# MSPM0G350X register map
Vendor: Texas Instruments; File version: This preliminary header file does not have a version number - build date: 2023-02-21 16:25:48
CPU: CM0 r0p1, little endian, MPU, no FPU, 3 interrupt priority bits
Registers are 32-bit, read-write, reset 0x0 unless marked. A register's access mark holds for its fields unless they carry their own. Offsets are from the block's base; [hi:lo] are bit positions; {n}, {i} and the like mark numbered series.

## CANFD0 (part 2 of 2) — PERIPHERALREGION
Base 0x40508000
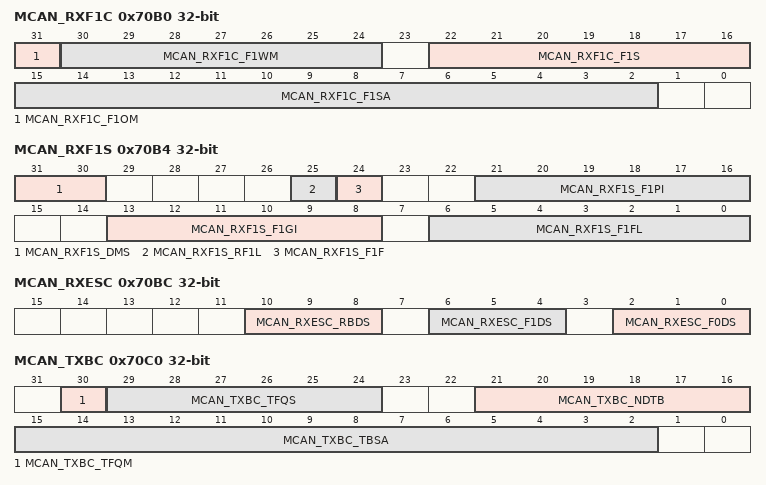
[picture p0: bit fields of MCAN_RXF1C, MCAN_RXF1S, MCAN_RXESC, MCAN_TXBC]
0x70B0 MCAN_RXF1C — MCAN Rx FIFO 1 Configuration
  [31] MCAN_RXF1C_F1OM — FIFO 1 Operation Mode. FIFO 1 can be operated in blocking or in overwrite mode. 0 FIFO 1 blocking mode 1 FIFO 1 overwrite mode Qualified Write is possible only with CCCR.CCE='1' and CCCR.INIT='1'.
  [30:24] MCAN_RXF1C_F1WM — Rx FIFO 1 Watermark 0 Watermark interrupt disabled 1-64 Level for Rx FIFO 1 watermark interrupt (IR.RF1W) >64 Watermark interrupt disabled Qualified Write is possible only with CCCR.CCE='1' and CCCR.INIT='1'.
  [22:16] MCAN_RXF1C_F1S — Rx FIFO 1 Size. The Rx FIFO 1 elements are indexed from 0 to F1S - 1. 0 No Rx FIFO 1 1-64 Number of Rx FIFO 1 elements >64 Values greater than 64 are interpreted as 64 Qualified Write is possible only with CCCR.CCE='1' and CCCR.INIT='1'.
  [15:2] MCAN_RXF1C_F1SA — Rx FIFO 1 Start Address Start address of Rx FIFO 1 in Message RAM (32-bit word address).
0x70B4 MCAN_RXF1S ro — MCAN Rx FIFO 1 Status
  [31:30] MCAN_RXF1S_DMS — Debug Message Status 00 Idle state, wait for reception of debug messages 01 Debug message A received 10 Debug messages A, B received 11 Debug messages A, B, C received
  [25] MCAN_RXF1S_RF1L — Rx FIFO 1 Message Lost. This bit is a copy of interrupt flag IR.RF1L. When IR.RF1L is reset, this bit is also reset. 0 No Rx FIFO 1 message lost 1 Rx FIFO 1 message lost, also set after write attempt to Rx FIFO 1 of size zero Note: Overwriting the oldest message when RXF1C.F1OM = '1' will not set this flag.
  [24] MCAN_RXF1S_F1F — Rx FIFO 1 Full 0 Rx FIFO 1 not full 1 Rx FIFO 1 full
  [21:16] MCAN_RXF1S_F1PI — Rx FIFO 1 Put Index. Rx FIFO 1 write index pointer, range 0 to 63.
  [13:8] MCAN_RXF1S_F1GI — Rx FIFO 1 Get Index. Rx FIFO 1 read index pointer, range 0 to 63.
  [6:0] MCAN_RXF1S_F1FL — Rx FIFO 1 Fill Level. Number of elements stored in Rx FIFO 1, range 0 to 64.
0x70B8 MCAN_RXF1A — MCAN Rx FIFO 1 Acknowledge
  [5:0] MCAN_RXF1A_F1AI — Rx FIFO 1 Acknowledge Index. After the Host has read a message or a sequence of messages from Rx FIFO 1 it has to write the buffer index of the last element read from Rx FIFO 1 to F1AI. This will set the Rx FIFO 1 Get Index RXF1S.F1GI to F1AI + 1 and update the FIFO 1 Fill Level RXF1S.F1FL.
0x70BC MCAN_RXESC — MCAN Rx Buffer / FIFO Element Size Configuration
  [10:8] MCAN_RXESC_RBDS — Rx Buffer Data Field Size 000 8 byte data field 001 12 byte data field 010 16 byte data field 011 20 byte data field 100 24 byte data field 101 32 byte data field 110 48 byte data field 111 64 byte data field Note: In case the data field size of an accepted CAN frame exceeds the data field size configured for the matching Rx Buffer or Rx FIFO, only the number of bytes as configured by RXESC are stored to the Rx Buffer resp. Rx FIFO element. The rest of the frame's data field is ignored. Qualified Write is possible only with CCCR.CCE='1' and CCCR.INIT='1'.
  [6:4] MCAN_RXESC_F1DS — Rx FIFO 1 Data Field Size 000 8 byte data field 001 12 byte data field 010 16 byte data field 011 20 byte data field 100 24 byte data field 101 32 byte data field 110 48 byte data field 111 64 byte data field Note: In case the data field size of an accepted CAN frame exceeds the data field size configured for the matching Rx Buffer or Rx FIFO, only the number of bytes as configured by RXESC are stored to the Rx Buffer resp. Rx FIFO element. The rest of the frame's data field is ignored. Qualified Write is possible only with CCCR.CCE='1' and CCCR.INIT='1'.
  [2:0] MCAN_RXESC_F0DS — Rx FIFO 0 Data Field Size 000 8 byte data field 001 12 byte data field 010 16 byte data field 011 20 byte data field 100 24 byte data field 101 32 byte data field 110 48 byte data field 111 64 byte data field Note: In case the data field size of an accepted CAN frame exceeds the data field size configured for the matching Rx Buffer or Rx FIFO, only the number of bytes as configured by RXESC are stored to the Rx Buffer resp. Rx FIFO element. The rest of the frame's data field is ignored. Qualified Write is possible only with CCCR.CCE='1' and CCCR.INIT='1'.
0x70C0 MCAN_TXBC — MCAN Tx Buffer Configuration
  [30] MCAN_TXBC_TFQM — Tx FIFO/Queue Mode 0 Tx FIFO operation 1 Tx Queue operation Qualified Write is possible only with CCCR.CCE='1' and CCCR.INIT='1'.
  [29:24] MCAN_TXBC_TFQS — Transmit FIFO/Queue Size 0 No Tx FIFO/Queue 1-32 Number of Tx Buffers used for Tx FIFO/Queue >32 Values greater than 32 are interpreted as 32 Note: Be aware that the sum of TFQS and NDTB may be not greater than 32. There is no check for erroneous configurations. The Tx Buffers section in the Message RAM starts with the dedicated Tx Buffers. Qualified Write is possible only with CCCR.CCE='1' and CCCR.INIT='1'.
  [21:16] MCAN_TXBC_NDTB — Number of Dedicated Transmit Buffers 0 No Dedicated Tx Buffers 1-32 Number of Dedicated Tx Buffers >32 Values greater than 32 are interpreted as 32 Note: Be aware that the sum of TFQS and NDTB may be not greater than 32. There is no check for erroneous configurations. The Tx Buffers section in the Message RAM starts with the dedicated Tx Buffers. Qualified Write is possible only with CCCR.CCE='1' and CCCR.INIT='1'.
  [15:2] MCAN_TXBC_TBSA — Tx Buffers Start Address. Start address of Tx Buffers section in Message RAM (32-bit word address). Qualified Write is possible only with CCCR.CCE='1' and CCCR.INIT='1'.
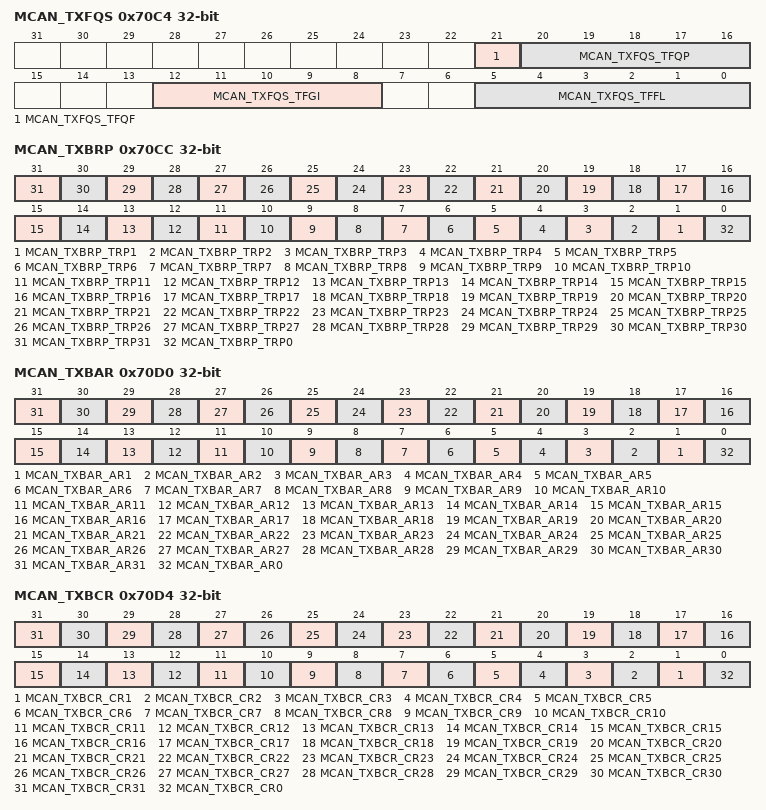
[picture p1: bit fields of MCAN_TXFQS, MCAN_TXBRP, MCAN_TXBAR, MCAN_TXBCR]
0x70C4 MCAN_TXFQS ro — MCAN Tx FIFO / Queue Status
  [21] MCAN_TXFQS_TFQF — Tx FIFO/Queue Full 0 Tx FIFO/Queue not full 1 Tx FIFO/Queue full
  [20:16] MCAN_TXFQS_TFQP — Tx FIFO/Queue Put Index. Tx FIFO/Queue write index pointer, range 0 to 31. Note: In case of mixed configurations where dedicated Tx Buffers are combined with a Tx FIFO or a Tx Queue, the Put and Get Indices indicate the number of the Tx Buffer starting with the first dedicated Tx Buffers. Example: For a configuration of 12 dedicated Tx Buffers and a Tx FIFO of 20 Buffers a Put Index of 15 points to the fourth buffer of the Tx FIFO.
  [12:8] MCAN_TXFQS_TFGI — Tx FIFO Get Index. Tx FIFO read index pointer, range 0 to 31. Read as zero when Tx Queue operation is configured (TXBC.TFQM = '1'). Note: In case of mixed configurations where dedicated Tx Buffers are combined with a Tx FIFO or a Tx Queue, the Put and Get Indices indicate the number of the Tx Buffer starting with the first dedicated Tx Buffers. Example: For a configuration of 12 dedicated Tx Buffers and a Tx FIFO of 20 Buffers a Put Index of 15 points to the fourth buffer of the Tx FIFO.
  [5:0] MCAN_TXFQS_TFFL — Tx FIFO Free Level. Number of consecutive free Tx FIFO elements starting from TFGI, range 0 to 32. Read as zero when Tx Queue operation is configured (TXBC.TFQM = '1').
0x70C8 MCAN_TXESC — MCAN Tx Buffer Element Size Configuration
  [2:0] MCAN_TXESC_TBDS — Tx Buffer Data Field Size 000 8 byte data field 001 12 byte data field 010 16 byte data field 011 20 byte data field 100 24 byte data field 101 32 byte data field 110 48 byte data field 111 64 byte data field Note: In case the data length code DLC of a Tx Buffer element is configured to a value higher than the Tx Buffer data field size TXESC.TBDS, the bytes not defined by the Tx Buffer are transmitted as &quot;0xCC&quot; (padding bytes). Qualified Write is possible only with CCCR.CCE='1' and CCCR.INIT='1'.
0x70CC MCAN_TXBRP ro — MCAN Tx Buffer Request Pending
  [n] MCAN_TXBRP_TRP{n} (n=1..31) — Transmission Request Pending {n}. See description for bit 0.
  [0] MCAN_TXBRP_TRP0 — Transmission Request Pending 0. Each Tx Buffer has its own Transmission Request Pending bit. The bits are set via register TXBAR. The bits are reset after a requested transmission has completed or has been cancelled via register TXBCR. TXBRP bits are set only for those Tx Buffers configured via TXBC. After a TXBRP bit has been set, a Tx scan is started to check for the pending Tx request with the highest priority (Tx Buffer with lowest Message ID). A cancellation request resets the corresponding transmission request pending bit of register TXBRP. In case a transmission has already been started when a cancellation is requested, this is done at the end of the transmission, regardless whether the transmission was successful or not. The cancellation request bits are reset directly after the corresponding TXBRP bit has been reset. After a cancellation has been requested, a finished cancellation is signalled via TXBCF - after successful transmission together with the corresponding TXBTO bit - when the transmission has not yet been started at the point of cancellation - when the transmission has been aborted due to lost arbitration - when an error occurred during frame transmission In DAR mode all transmissions are automatically cancelled if they are not successful. The corresponding TXBCF bit is set for all unsuccessful transmissions. 0 No transmission request pending 1 Transmission request pending Note: TXBRP bits which are set while a Tx scan is in progress are not considered during this particular Tx scan. In case a cancellation is requested for such a Tx Buffer, this Add Request is cancelled immediately, the corresponding TXBRP bit is reset.
0x70D0 MCAN_TXBAR — MCAN Tx Buffer Add Request
  [n] MCAN_TXBAR_AR{n} (n=1..31) — Add Request {n}. See description for bit 0.
  [0] MCAN_TXBAR_AR0 — Add Request 0. Each Tx Buffer has its own Add Request bit. Writing a '1' will set the corresponding Add Request bit; writing a '0' has no impact. This enables the Host to set transmission requests for multiple Tx Buffers with one write to TXBAR. TXBAR bits are set only for those Tx Buffers configured via TXBC. When no Tx scan is running, the bits are reset immediately, else the bits remain set until the Tx scan process has completed. 0 No transmission request added 1 Transmission requested added Note: If an add request is applied for a Tx Buffer with pending transmission request (corresponding TXBRP bit already set), this add request is ignored. Qualified Write is possible only with CCCR.CCE='0'
0x70D4 MCAN_TXBCR — MCAN Tx Buffer Cancellation Request
  [n] MCAN_TXBCR_CR{n} (n=1..31) — Cancellation Request {n}. See description for bit 0.
  [0] MCAN_TXBCR_CR0 — Cancellation Request 0. Each Tx Buffer has its own Cancellation Request bit. Writing a '1' will set the corresponding Cancellation Request bit; writing a '0' has no impact. This enables the Host to set cancellation requests for multiple Tx Buffers with one write to TXBCR. TXBCR bits are set only for those Tx Buffers configured via TXBC. The bits remain set until the corresponding bit of TXBRP is reset. 0 No cancellation pending 1 Cancellation pending Qualified Write is possible only with CCCR.CCE='0'
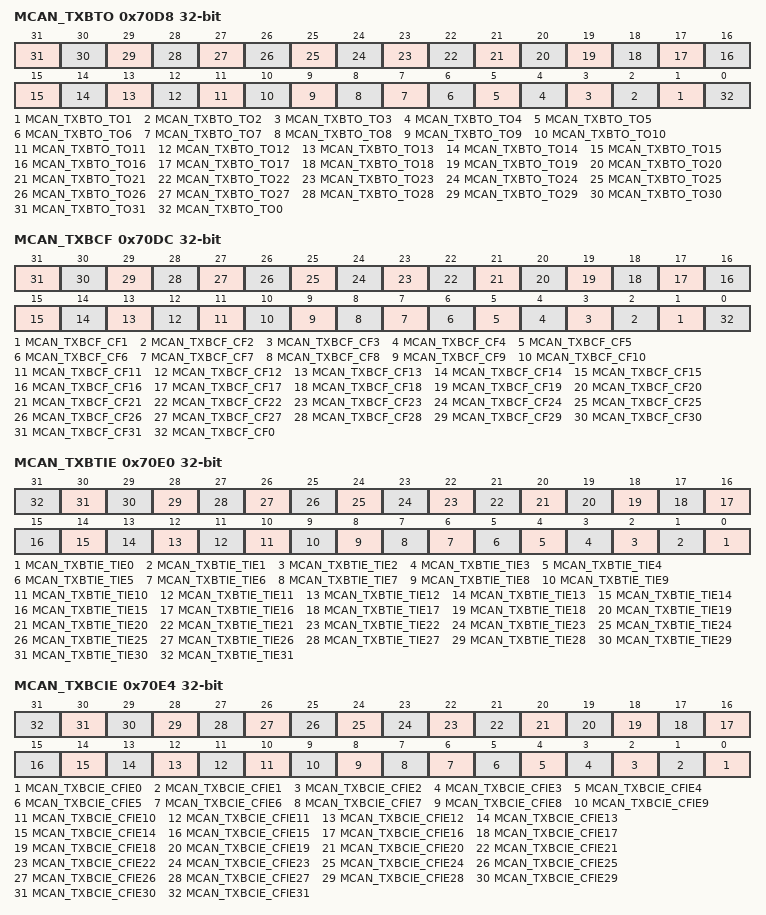
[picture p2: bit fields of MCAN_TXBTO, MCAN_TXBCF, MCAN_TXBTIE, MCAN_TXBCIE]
0x70D8 MCAN_TXBTO ro — MCAN Tx Buffer Transmission Occurred
  [n] MCAN_TXBTO_TO{n} (n=1..31) — Transmission Occurred {n}. See description for bit 0.
  [0] MCAN_TXBTO_TO0 — Transmission Occurred 0. Each Tx Buffer has its own Transmission Occurred bit. The bits are set when the corresponding TXBRP bit is cleared after a successful transmission. The bits are reset when a new transmission is requested by writing a '1' to the corresponding bit of register TXBAR. 0 No transmission occurred 1 Transmission occurred
0x70DC MCAN_TXBCF ro — MCAN Tx Buffer Cancellation Finished
  [n] MCAN_TXBCF_CF{n} (n=1..31) — Cancellation Finished {n}. See description for bit 0.
  [0] MCAN_TXBCF_CF0 — Cancellation Finished 0. Each Tx Buffer has its own Cancellation Finished bit. The bits are set when the corresponding TXBRP bit is cleared after a cancellation was requested via TXBCR. In case the corresponding TXBRP bit was not set at the point of cancellation, CF is set immediately. The bits are reset when a new transmission is requested by writing a '1' to the corresponding bit of register TXBAR. 0 No transmit buffer cancellation 1 Transmit buffer cancellation finished
0x70E0 MCAN_TXBTIE — MCAN Tx Buffer Transmission Interrupt Enable
  [n] MCAN_TXBTIE_TIE{n} (n=0..31) — Transmission Interrupt Enable {n}. Each Tx Buffer has its own Transmission Interrupt Enable bit. 0 Transmission interrupt disabled 1 Transmission interrupt enable
0x70E4 MCAN_TXBCIE — MCAN Tx Buffer Cancellation Finished Interrupt Enable
  [n] MCAN_TXBCIE_CFIE{n} (n=0..31) — Cancellation Finished Interrupt Enable {n}. Each Tx Buffer has its own Cancellation Finished Interrupt Enable bit. 0 Cancellation finished interrupt disabled 1 Cancellation finished interrupt enabled
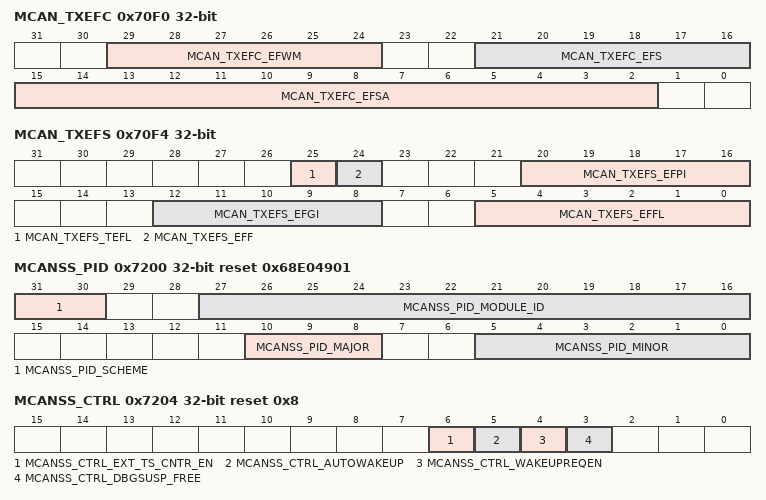
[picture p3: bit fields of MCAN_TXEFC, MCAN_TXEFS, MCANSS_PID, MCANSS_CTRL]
0x70F0 MCAN_TXEFC — MCAN Tx Event FIFO Configuration
  [29:24] MCAN_TXEFC_EFWM — Event FIFO Watermark 0 Watermark interrupt disabled 1-32 Level for Tx Event FIFO watermark interrupt (IR.TEFW) >32 Watermark interrupt disabled
  [21:16] MCAN_TXEFC_EFS — Event FIFO Size. The Tx Event FIFO elements are indexed from 0 to EFS - 1. 0 Tx Event FIFO disabled 1-32 Number of Tx Event FIFO elements >32 Values greater than 32 are interpreted as 32
  [15:2] MCAN_TXEFC_EFSA — Event FIFO Start Address. Start address of Tx Event FIFO in Message RAM (32-bit word address).
0x70F4 MCAN_TXEFS ro — MCAN Tx Event FIFO Status
  [25] MCAN_TXEFS_TEFL — Tx Event FIFO Element Lost. This bit is a copy of interrupt flag IR.TEFL. When IR.TEFL is reset, this bit is also reset. 0 No Tx Event FIFO element lost 1 Tx Event FIFO element lost, also set after write attempt to Tx Event FIFO of size zero.
  [24] MCAN_TXEFS_EFF — Event FIFO Full 0 Tx Event FIFO not full 1 Tx Event FIFO full
  [20:16] MCAN_TXEFS_EFPI — Event FIFO Put Index.Tx Event FIFO write index pointer, range 0 to 31.
  [12:8] MCAN_TXEFS_EFGI — Event FIFO Get Index. Tx Event FIFO read index pointer, range 0 to 31.
  [5:0] MCAN_TXEFS_EFFL — Event FIFO Fill Level. Number of elements stored in Tx Event FIFO, range 0 to 32.
0x70F8 MCAN_TXEFA — MCAN Tx Event FIFO Acknowledge
  [4:0] MCAN_TXEFA_EFAI — Event FIFO Acknowledge Index. After the Host has read an element or a sequence of elements from the Tx Event FIFO it has to write the index of the last element read from Tx Event FIFO to EFAI. This will set the Tx Event FIFO Get Index TXEFS.EFGI to EFAI + 1 and update the Event FIFO Fill Level TXEFS.EFFL.
0x7200 MCANSS_PID ro reset 0x68E04901 — MCAN Subsystem Revision Register
  [31:30] MCANSS_PID_SCHEME — PID Register Scheme
  [27:16] MCANSS_PID_MODULE_ID — Module Identification Number
  [10:8] MCANSS_PID_MAJOR — Major Revision of the MCAN Subsystem
  [5:0] MCANSS_PID_MINOR — Minor Revision of the MCAN Subsystem
0x7204 MCANSS_CTRL reset 0x8 — MCAN Subsystem Control Register
  [6] MCANSS_CTRL_EXT_TS_CNTR_EN — External Timestamp Counter Enable. 0 External timestamp counter disabled 1 External timestamp counter enabled
  [5] MCANSS_CTRL_AUTOWAKEUP — Automatic Wakeup Enable. Enables the MCANSS to automatically clear the MCAN CCCR.INIT bit, fully waking the MCAN up, on an enabled wakeup request. 0 Disable the automatic write to CCCR.INIT 1 Enable the automatic write to CCCR.INIT
  [4] MCANSS_CTRL_WAKEUPREQEN — Wakeup Request Enable. Enables the MCANSS to wakeup on CAN RXD activity. 0 Disable wakeup request 1 Enables wakeup request
  [3] MCANSS_CTRL_DBGSUSP_FREE — Debug Suspend Free Bit. Enables debug suspend. 0 Disable debug suspend 1 Enable debug suspend
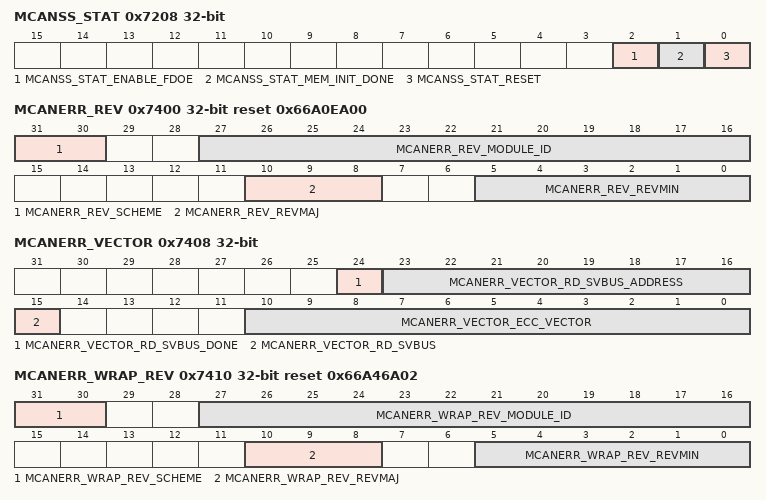
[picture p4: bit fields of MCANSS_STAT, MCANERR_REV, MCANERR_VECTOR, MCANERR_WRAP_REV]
0x7208 MCANSS_STAT ro (reset mask 0xFFFFFFFB) — MCAN Subsystem Status Register
  [2] MCANSS_STAT_ENABLE_FDOE — Flexible Datarate Operation Enable. Determines whether CAN FD operation may be enabled via the MCAN core CCCR.FDOE bit (bit 8) or if only standard CAN operation is possible with this instance of the MCAN. 0 MCAN is only capable of standard CAN communication 1 MCAN may be configured to perform CAN FD communication
  [1] MCANSS_STAT_MEM_INIT_DONE — Memory Initialization Done. 0 Message RAM initialization is in progress 1 Message RAM is initialized for use
  [0] MCANSS_STAT_RESET — Soft Reset Status. 0 Not in reset 1 Reset is in progress
0x720C MCANSS_ICS — MCAN Subsystem Interrupt Clear Shadow Register
  [0] MCANSS_ICS_EXT_TS_CNTR_OVFL — External Timestamp Counter Overflow Interrupt Status Clear. Reads always return a 0. 0 Write of '0' has no effect 1 Write of '1' clears the MCANSS_IRS.EXT_TS_CNTR_OVFL bit
0x7210 MCANSS_IRS — MCAN Subsystem Interrupt Raw Satus Register
  [0] MCANSS_IRS_EXT_TS_CNTR_OVFL — External Timestamp Counter Overflow Interrupt Status. This bit is set by HW or by a SW write of '1'. To clear, use the MCANSS_ICS.EXT_TS_CNTR_OVFL bit. 0 External timestamp counter has not overflowed 1 External timestamp counter has overflowed When this bit is set to '1' by HW or SW, the MCANSS_EXT_TS_UNSERVICED_INTR_CNTR.EXT_TS_INTR_CNTR bit field will increment by 1.
0x7214 MCANSS_IECS — MCAN Subsystem Interrupt Enable Clear Shadow Register
  [0] MCANSS_IECS_EXT_TS_CNTR_OVFL — External Timestamp Counter Overflow Interrupt Enable Clear. Reads always return a 0. 0 Write of '0' has no effect 1 Write of '1' clears the MCANSS_IES.EXT_TS_CNTR_OVFL bit
0x7218 MCANSS_IE — MCAN Subsystem Interrupt Enable Register
  [0] MCANSS_IE_EXT_TS_CNTR_OVFL — External Timestamp Counter Overflow Interrupt Enable. A write of '0' has no effect. A write of '1' sets the MCANSS_IES.EXT_TS_CNTR_OVFL bit.
0x721C MCANSS_IES ro — MCAN Subsystem Interrupt Enable Status
  [0] MCANSS_IES_EXT_TS_CNTR_OVFL — External Timestamp Counter Overflow Interrupt Enable Status. To set, use the CANSS_IE.EXT_TS_CNTR_OVFL bit. To clear, use the MCANSS_IECS.EXT_TS_CNTR_OVFL bit. 0 External timestamp counter overflow interrupt is not enabled 1 External timestamp counter overflow interrupt is enabled
0x7220 MCANSS_EOI — MCAN Subsystem End of Interrupt
  [7:0] MCANSS_EOI_EOI — End of Interrupt. A write to this register will clear the associated interrupt. If the unserviced interrupt counter is > 1, another interrupt is generated. 0x00 External TS Interrupt is cleared 0x01 MCAN(0) interrupt is cleared 0x02 MCAN(1) interrupt is cleared Other writes are ignored.
0x7224 MCANSS_EXT_TS_PRESCALER — MCAN Subsystem External Timestamp Prescaler 0
  [23:0] MCANSS_EXT_TS_PRESCALER_PRESCALER — External Timestamp Prescaler Reload Value. The external timestamp count rate is the host (system) clock rate divided by this value, except in the case of 0. A zero value in this bit field will act identically to a value of 0x000001.
0x7228 MCANSS_EXT_TS_UNSERVICED_INTR_CNTR ro — MCAN Subsystem External Timestamp Unserviced Interrupts Counter
  [4:0] MCANSS_EXT_TS_UNSERVICED_INTR_CNTR_EXT_TS_INTR_CNTR — External Timestamp Counter Unserviced Rollover Interrupts. If this value is > 1, an MCANSS_EOI write of '1' to bit 0 will issue another interrupt. The status of this bit field is affected by the MCANSS_IRS.EXT_TS_CNTR_OVFL bit field.
0x7400 MCANERR_REV ro reset 0x66A0EA00 — MCAN Error Aggregator Revision Register
  [31:30] MCANERR_REV_SCHEME — PID Register Scheme
  [27:16] MCANERR_REV_MODULE_ID — Module Identification Number
  [10:8] MCANERR_REV_REVMAJ — Major Revision of the Error Aggregator
  [5:0] MCANERR_REV_REVMIN — Minor Revision of the Error Aggregator
0x7408 MCANERR_VECTOR — MCAN ECC Vector Register
  [24] MCANERR_VECTOR_RD_SVBUS_DONE ro — Read Completion Flag
  [23:16] MCANERR_VECTOR_RD_SVBUS_ADDRESS — Read Address Offset
  [15] MCANERR_VECTOR_RD_SVBUS — Read Trigger
  [10:0] MCANERR_VECTOR_ECC_VECTOR — ECC RAM ID. Each error detection and correction (EDC) controller has a bank of error registers (offsets 0x10 - 0x3B) associated with it. These registers are accessed via an internal serial bus (SVBUS). To access them through the ECC aggregator the controller ID desired must be written to the ECC_VECTOR field, together with the RD_SVBUS trigger and RD_SVBUS_ADDRESS bit field. This initiates the serial read which consummates by setting the RD_SVBUS_DONE bit. At this point the addressed register may be read by a normal CPU read of the appropriate offset address. 0x000 Message RAM ECC controller is selected Others Reserved (do not use) Subsequent writes through the SVBUS (offsets 0x10 - 0x3B) have a delayed completion. To avoid conflicts, perform a read back of a register within this range after writing.
0x740C MCANERR_STAT ro reset 0x2 — MCAN Error Misc Status
  [10:0] MCANERR_STAT_NUM_RAMS — Number of RAMs. Number of ECC RAMs serviced by the aggregator.
0x7410 MCANERR_WRAP_REV ro reset 0x66A46A02 — MCAN ECC Wrapper Revision Register
  [31:30] MCANERR_WRAP_REV_SCHEME — PID Register Scheme
  [27:16] MCANERR_WRAP_REV_MODULE_ID — Module Identification Number
  [10:8] MCANERR_WRAP_REV_REVMAJ — Major Revision of the Error Aggregator
  [5:0] MCANERR_WRAP_REV_REVMIN — Minor Revision of the Error Aggregator
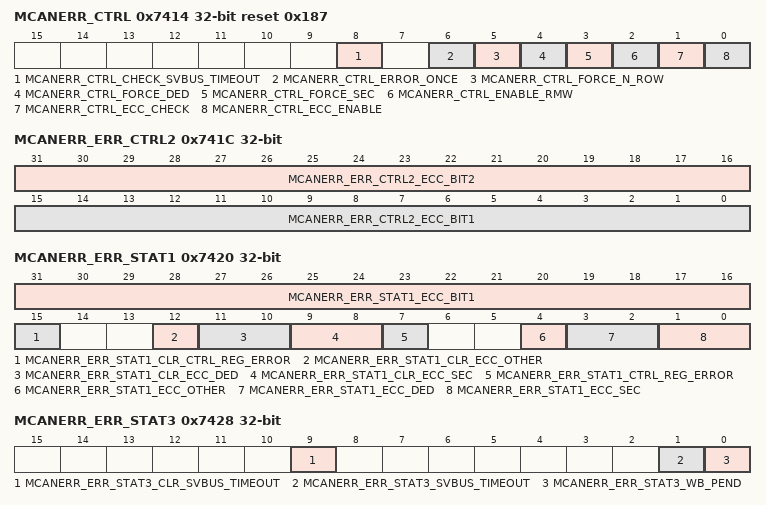
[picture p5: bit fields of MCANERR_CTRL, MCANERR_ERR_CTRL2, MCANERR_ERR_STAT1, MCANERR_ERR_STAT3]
0x7414 MCANERR_CTRL reset 0x187 — MCAN ECC Control
  [8] MCANERR_CTRL_CHECK_SVBUS_TIMEOUT — Enables Serial VBUS timeout mechanism
  [6] MCANERR_CTRL_ERROR_ONCE — If this bit is set, the FORCE_SEC/FORCE_DED will inject an error to the specified row only once. The FORCE_SEC bit will be cleared once a writeback happens. If writeback is not enabled, this error will be cleared the cycle following the read when the data is corrected. For double-bit errors, the FORCE_DED bit will be cleared the cycle following the double-bit error. Any subsequent reads will not force an error.
  [5] MCANERR_CTRL_FORCE_N_ROW — Enable single/double-bit error on the next RAM read, regardless of the MCANERR_ERR_CTRL1.ECC_ROW setting. For write through mode, this applies to writes as well as reads.
  [4] MCANERR_CTRL_FORCE_DED — Force double-bit error. Cleared the cycle following the error if ERROR_ONCE is asserted. For write through mode, this applies to writes as well as reads. MCANERR_ERR_CTRL1 and MCANERR_ERR_CTRL2 should be configured prior to setting this bit.
  [3] MCANERR_CTRL_FORCE_SEC — Force single-bit error. Cleared on a writeback or the cycle following the error if ERROR_ONCE is asserted. For write through mode, this applies to writes as well as reads. MCANERR_ERR_CTRL1 and MCANERR_ERR_CTRL2 should be configured prior to setting this bit.
  [2] MCANERR_CTRL_ENABLE_RMW — Enable read-modify-write on partial word writes
  [1] MCANERR_CTRL_ECC_CHECK — Enable ECC Check. ECC is completely bypassed if both ECC_ENABLE and ECC_CHECK are '0'.
  [0] MCANERR_CTRL_ECC_ENABLE — Enable ECC Generation
0x7418 MCANERR_ERR_CTRL1 — MCAN ECC Error Control 1 Register
  [31:0] MCANERR_ERR_CTRL1_ECC_ROW — Row address where FORCE_SEC or FORCE_DED needs to be applied. This is ignored if FORCE_N_ROW is set.
0x741C MCANERR_ERR_CTRL2 — MCAN ECC Error Control 2 Register
  [31:16] MCANERR_ERR_CTRL2_ECC_BIT2 — Second column/data bit that needs to be flipped when FORCE_DED is set
  [15:0] MCANERR_ERR_CTRL2_ECC_BIT1 — Column/Data bit that needs to be flipped when FORCE_SEC or FORCE_DED is set
0x7420 MCANERR_ERR_STAT1 — MCAN ECC Error Status 1 Register
  [31:16] MCANERR_ERR_STAT1_ECC_BIT1 ro — ECC Error Bit Position. Indicates the bit position in the RAM data that is in error on an SEC error. Only valid on an SEC error. 0 Bit 0 is in error 1 Bit 1 is in error 2 Bit 2 is in error 3 Bit 3 is in error ... 31 Bit 31 is in error >32 Invalid
  [15] MCANERR_ERR_STAT1_CLR_CTRL_REG_ERROR — Writing a '1' clears the CTRL_REG_ERROR bit
  [12] MCANERR_ERR_STAT1_CLR_ECC_OTHER — Writing a '1' clears the ECC_OTHER bit.
  [11:10] MCANERR_ERR_STAT1_CLR_ECC_DED — Clear ECC_DED. A write of a non-zero value to this bit field decrements the ECC_DED bit field by the value provided.
  [9:8] MCANERR_ERR_STAT1_CLR_ECC_SEC — Clear ECC_SEC. A write of a non-zero value to this bit field decrements the ECC_SEC bit field by the value provided.
  [7] MCANERR_ERR_STAT1_CTRL_REG_ERROR — Control Register Error. A bit field in the control register is in an ambiguous state. This means that the redundancy registers have detected a state where not all values are the same and has defaulted to the reset state. S/W needs to re-write these registers to a known state. A write of 1 will set this interrupt flag.
  [4] MCANERR_ERR_STAT1_ECC_OTHER — SEC While Writeback Error Status 0 No SEC error while writeback pending 1 Indicates that successive single-bit errors have occurred while a writeback is still pending
  [3:2] MCANERR_ERR_STAT1_ECC_DED — Double Bit Error Detected Status. A 2-bit saturating counter of the number of DED errors that have occurred since last cleared. 0 No double-bit error detected 1 One double-bit error was detected 2 Two double-bit errors were detected 3 Three double-bit errors were detected A write of a non-zero value to this bit field increments it by the value provided.
  [1:0] MCANERR_ERR_STAT1_ECC_SEC — Single Bit Error Corrected Status. A 2-bit saturating counter of the number of SEC errors that have occurred since last cleared. 0 No single-bit error detected 1 One single-bit error was detected and corrected 2 Two single-bit errors were detected and corrected 3 Three single-bit errors were detected and corrected A write of a non-zero value to this bit field increments it by the value provided.
0x7424 MCANERR_ERR_STAT2 ro — MCAN ECC Error Status 2 Register
  [31:0] MCANERR_ERR_STAT2_ECC_ROW — Indicates the row address where the single or double-bit error occurred. This value is address offset/4.
0x7428 MCANERR_ERR_STAT3 — MCAN ECC Error Status 3 Register
  [9] MCANERR_ERR_STAT3_CLR_SVBUS_TIMEOUT — Write 1 to clear the Serial VBUS Timeout Flag
  [1] MCANERR_ERR_STAT3_SVBUS_TIMEOUT — Serial VBUS Timeout Flag. Write 1 to set.
  [0] MCANERR_ERR_STAT3_WB_PEND ro — Delayed Write Back Pending Status 0 No write back pending 1 An ECC data correction write back is pending
0x743C MCANERR_SEC_EOI — MCAN Single Error Corrected End of Interrupt Register
  [0] MCANERR_SEC_EOI_EOI_WR — Write to this register indicates that software has acknowledged the pending interrupt and the next interrupt can be sent to the host. Note that a write to the MCANERR_ERR_STAT1.CLR_ECC_SEC goes through the SVBUS and has a delayed completion. To avoid an additional interrupt, read the MCANERR_ERR_STAT1 register back prior to writing to this bit field.
0x7440 MCANERR_SEC_STATUS — MCAN Single Error Corrected Interrupt Status Register
  [0] MCANERR_SEC_STATUS_MSGMEM_PEND ro — Message RAM SEC Interrupt Pending 0 No SEC interrupt is pending 1 SEC interrupt is pending
0x7480 MCANERR_SEC_ENABLE_SET — MCAN Single Error Corrected Interrupt Enable Set Register
  [0] MCANERR_SEC_ENABLE_SET_MSGMEM_ENABLE_SET — Message RAM SEC Interrupt Pending Enable Set. Writing a 1 to this bit enables the Message RAM SEC error interrupts. Writing a 0 has no effect. Reads return the corresponding enable bit's current value.
0x74C0 MCANERR_SEC_ENABLE_CLR — MCAN Single Error Corrected Interrupt Enable Clear Register
  [0] MCANERR_SEC_ENABLE_CLR_MSGMEM_ENABLE_CLR — Message RAM SEC Interrupt Pending Enable Clear. Writing a 1 to this bit disables the Message RAM SEC error interrupts. Writing a 0 has no effect. Reads return the corresponding enable bit's current value.
0x753C MCANERR_DED_EOI — MCAN Double Error Detected End of Interrupt Register
  [0] MCANERR_DED_EOI_EOI_WR — Write to this register indicates that software has acknowledged the pending interrupt and the next interrupt can be sent to the host. Note that a write to the MCANERR_ERR_STAT1.CLR_ECC_DED goes through the SVBUS and has a delayed completion. To avoid an additional interrupt, read the MCANERR_ERR_STAT1 register back prior to writing to this bit field.
0x7540 MCANERR_DED_STATUS — MCAN Double Error Detected Interrupt Status Register
  [0] MCANERR_DED_STATUS_MSGMEM_PEND ro — Message RAM DED Interrupt Pending 0 No DED interrupt is pending 1 DED interrupt is pending
0x7580 MCANERR_DED_ENABLE_SET — MCAN Double Error Detected Interrupt Enable Set Register
  [0] MCANERR_DED_ENABLE_SET_MSGMEM_ENABLE_SET — Message RAM DED Interrupt Pending Enable Set. Writing a 1 to this bit enables the Message RAM DED error interrupts. Writing a 0 has no effect. Reads return the corresponding enable bit's current value.
0x75C0 MCANERR_DED_ENABLE_CLR — MCAN Double Error Detected Interrupt Enable Clear Register
  [0] MCANERR_DED_ENABLE_CLR_MSGMEM_ENABLE_CLR — Message RAM DED Interrupt Pending Enable Clear. Writing a 1 to this bit disables the Message RAM DED error interrupts. Writing a 0 has no effect. Reads return the corresponding enable bit's current value.
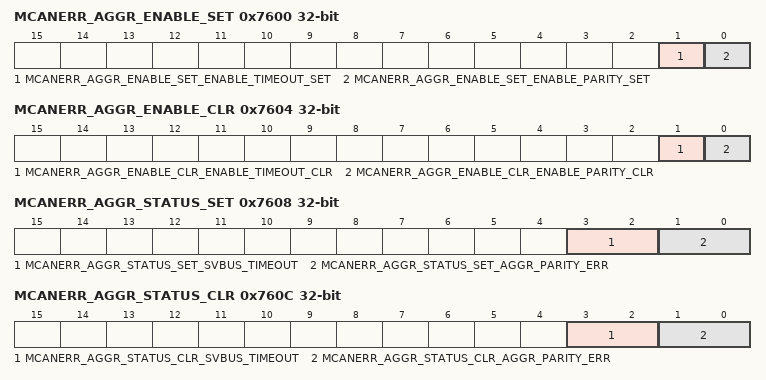
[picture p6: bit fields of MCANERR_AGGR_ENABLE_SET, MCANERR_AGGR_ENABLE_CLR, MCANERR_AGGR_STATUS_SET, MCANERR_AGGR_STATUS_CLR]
0x7600 MCANERR_AGGR_ENABLE_SET — MCAN Error Aggregator Enable Set Register
  [1] MCANERR_AGGR_ENABLE_SET_ENABLE_TIMEOUT_SET — Write 1 to enable timeout errors. Reads return the corresponding enable bit's current value.
  [0] MCANERR_AGGR_ENABLE_SET_ENABLE_PARITY_SET — Write 1 to enable parity errors. Reads return the corresponding enable bit's current value.
0x7604 MCANERR_AGGR_ENABLE_CLR — MCAN Error Aggregator Enable Clear Register
  [1] MCANERR_AGGR_ENABLE_CLR_ENABLE_TIMEOUT_CLR — Write 1 to disable timeout errors. Reads return the corresponding enable bit's current value.
  [0] MCANERR_AGGR_ENABLE_CLR_ENABLE_PARITY_CLR — Write 1 to disable parity errors. Reads return the corresponding enable bit's current value.
0x7608 MCANERR_AGGR_STATUS_SET — MCAN Error Aggregator Status Set Register
  [3:2] MCANERR_AGGR_STATUS_SET_SVBUS_TIMEOUT — Aggregator Serial VBUS Timeout Error Status 2-bit saturating counter of the number of SVBUS timeout errors that have occurred since last cleared. 0 No timeout errors have occurred 1 One timeout error has occurred 2 Two timeout errors have occurred 3 Three timeout errors have occurred A write of a non-zero value to this bit field increments it by the value provided.
  [1:0] MCANERR_AGGR_STATUS_SET_AGGR_PARITY_ERR — Aggregator Parity Error Status 2-bit saturating counter of the number of parity errors that have occurred since last cleared. 0 No parity errors have occurred 1 One parity error has occurred 2 Two parity errors have occurred 3 Three parity errors have occurred A write of a non-zero value to this bit field increments it by the value provided.
0x760C MCANERR_AGGR_STATUS_CLR — MCAN Error Aggregator Status Clear Register
  [3:2] MCANERR_AGGR_STATUS_CLR_SVBUS_TIMEOUT — Aggregator Serial VBUS Timeout Error Status 2-bit saturating counter of the number of SVBUS timeout errors that have occurred since last cleared. 0 No timeout errors have occurred 1 One timeout error has occurred 2 Two timeout errors have occurred 3 Three timeout errors have occurred A write of a non-zero value to this bit field decrements it by the value provided.
  [1:0] MCANERR_AGGR_STATUS_CLR_AGGR_PARITY_ERR — Aggregator Parity Error Status 2-bit saturating counter of the number of parity errors that have occurred since last cleared. 0 No parity errors have occurred 1 One parity error has occurred 2 Two parity errors have occurred 3 Three parity errors have occurred A write of a non-zero value to this bit field decrements it by the value provided.
0x7820 IIDX ro — Interrupt Index Register
  [7:0] IIDX_STAT — Interrupt index status
    0=IIDX_STAT_NO_INTR (NO_INTR); 1=IIDX_STAT_INTL0 (INTL0); 2=IIDX_STAT_INTL1 (INTL1); 3=IIDX_STAT_SEC (SEC); 4=IIDX_STAT_DED (DED); 5=IIDX_STAT_EXT_TS_CNTR_OVFL (EXT_TS_CNTR_OVFL); 6=IIDX_STAT_WAKEUP (WAKEUP)
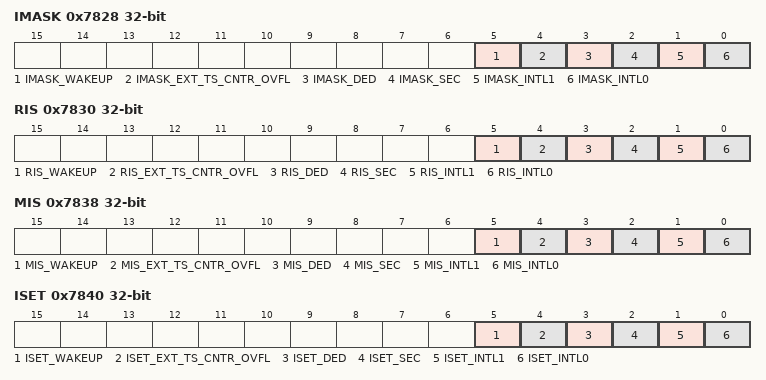
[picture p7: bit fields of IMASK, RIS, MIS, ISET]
0x7828 IMASK — Interrupt mask
  [5] IMASK_WAKEUP — Clock Stop Wake Up interrupt mask.
    0=IMASK_WAKEUP_CLR (CLR); 1=IMASK_WAKEUP_SET (SET)
  [4] IMASK_EXT_TS_CNTR_OVFL — External Timestamp Counter Overflow interrupt mask.
    0=IMASK_EXT_TS_CNTR_OVFL_CLR (CLR); 1=IMASK_EXT_TS_CNTR_OVFL_SET (SET)
  [3] IMASK_DED — Massage RAM DED interrupt mask.
    0=IMASK_DED_CLR (CLR); 1=IMASK_DED_SET (SET)
  [2] IMASK_SEC — Message RAM SEC interrupt mask.
    0=IMASK_SEC_CLR (CLR); 1=IMASK_SEC_SET (SET)
  [1] IMASK_INTL1 — MCAN Interrupt Line 1 mask.
    0=IMASK_INTL1_CLR (CLR); 1=IMASK_INTL1_SET (SET)
  [0] IMASK_INTL0 — MCAN Interrupt Line 0 mask.
    0=IMASK_INTL0_CLR (CLR); 1=IMASK_INTL0_SET (SET)
0x7830 RIS ro — Raw interrupt status
  [5] RIS_WAKEUP — Clock Stop Wake Up interrupt.
    0=RIS_WAKEUP_CLR (CLR); 1=RIS_WAKEUP_SET (SET)
  [4] RIS_EXT_TS_CNTR_OVFL — External Timestamp Counter Overflow interrupt.
    0=RIS_EXT_TS_CNTR_OVFL_CLR (CLR); 1=RIS_EXT_TS_CNTR_OVFL_SET (SET)
  [3] RIS_DED — Message RAM DED interrupt.
    0=RIS_DED_CLR (CLR); 1=RIS_DED_SET (SET)
  [2] RIS_SEC — Message RAM SEC interrupt.
    0=RIS_SEC_CLR (CLR); 1=RIS_SEC_SET (SET)
  [1] RIS_INTL1 — MCAN Interrupt Line 1.
    0=RIS_INTL1_CLR (CLR); 1=RIS_INTL1_SET (SET)
  [0] RIS_INTL0 — MCAN Interrupt Line 0.
    0=RIS_INTL0_CLR (CLR); 1=RIS_INTL0_SET (SET)
0x7838 MIS ro — Masked interrupt status
  [5] MIS_WAKEUP — Masked Clock Stop Wake Up interrupt.
    0=MIS_WAKEUP_CLR (CLR); 1=MIS_WAKEUP_SET (SET)
  [4] MIS_EXT_TS_CNTR_OVFL — Masked External Timestamp Counter Overflow interrupt.
    0=MIS_EXT_TS_CNTR_OVFL_CLR (CLR); 1=MIS_EXT_TS_CNTR_OVFL_SET (SET)
  [3] MIS_DED — Masked Message RAM DED interrupt.
    0=MIS_DED_CLR (CLR); 1=MIS_DED_SET (SET)
  [2] MIS_SEC — Masked Message RAM SEC interrupt.
    0=MIS_SEC_CLR (CLR); 1=MIS_SEC_SET (SET)
  [1] MIS_INTL1 — Masked MCAN Interrupt Line 1.
    0=MIS_INTL1_CLR (CLR); 1=MIS_INTL1_SET (SET)
  [0] MIS_INTL0 — Masked MCAN Interrupt Line 0.
    0=MIS_INTL0_CLR (CLR); 1=MIS_INTL0_SET (SET)
0x7840 ISET wo — Interrupt set
  [5] ISET_WAKEUP — Set Clock Stop Wake Up interrupt.
    0=ISET_WAKEUP_NO_EFFECT (NO_EFFECT); 1=ISET_WAKEUP_SET (SET)
  [4] ISET_EXT_TS_CNTR_OVFL — Set External Timestamp Counter Overflow interrupt.
    0=ISET_EXT_TS_CNTR_OVFL_NO_EFFECT (NO_EFFECT); 1=ISET_EXT_TS_CNTR_OVFL_SET (SET)
  [3] ISET_DED — Set Message RAM DED interrupt.
    0=ISET_DED_NO_EFFECT (NO_EFFECT); 1=ISET_DED_SET (SET)
  [2] ISET_SEC — Set Message RAM SEC interrupt.
    0=ISET_SEC_NO_EFFECT (NO_EFFECT); 1=ISET_SEC_SET (SET)
  [1] ISET_INTL1 — Set MCAN Interrupt Line 1.
    0=ISET_INTL1_NO_EFFECT (NO_EFFECT); 1=ISET_INTL1_SET (SET)
  [0] ISET_INTL0 — Set MCAN Interrupt Line 0.
    0=ISET_INTL0_NO_EFFECT (NO_EFFECT); 1=ISET_INTL0_SET (SET)
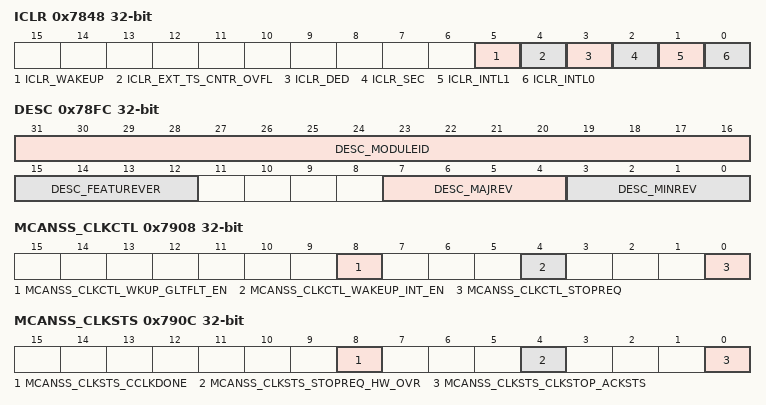
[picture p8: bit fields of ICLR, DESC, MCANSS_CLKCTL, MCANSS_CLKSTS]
0x7848 ICLR wo — Interrupt clear
  [5] ICLR_WAKEUP — Clear Clock Stop Wake Up interrupt.
    0=ICLR_WAKEUP_NO_EFFECT (NO_EFFECT); 1=ICLR_WAKEUP_CLR (CLR)
  [4] ICLR_EXT_TS_CNTR_OVFL — Clear External Timestamp Counter Overflow interrupt.
    0=ICLR_EXT_TS_CNTR_OVFL_NO_EFFECT (NO_EFFECT); 1=ICLR_EXT_TS_CNTR_OVFL_CLR (CLR)
  [3] ICLR_DED — Clear Message RAM DED interrupt.
    0=ICLR_DED_NO_EFFECT (NO_EFFECT); 1=ICLR_DED_CLR (CLR)
  [2] ICLR_SEC — Clear Message RAM SEC interrupt.
    0=ICLR_SEC_NO_EFFECT (NO_EFFECT); 1=ICLR_SEC_CLR (CLR)
  [1] ICLR_INTL1 — Clear MCAN Interrupt Line 1.
    0=ICLR_INTL1_NO_EFFECT (NO_EFFECT); 1=ICLR_INTL1_CLR (CLR)
  [0] ICLR_INTL0 — Clear MCAN Interrupt Line 0.
    0=ICLR_INTL0_NO_EFFECT (NO_EFFECT); 1=ICLR_INTL0_CLR (CLR)
0x78E0 EVT_MODE — Event Mode
  [1:0] EVT_MODE_INT0_CFG ro — Event line mode select for event corresponding to [IPSTANDARD.INT_EVENT0]
    0=EVT_MODE_INT0_CFG_DISABLE (DISABLE); 1=EVT_MODE_INT0_CFG_SOFTWARE (SOFTWARE); 2=EVT_MODE_INT0_CFG_HARDWARE (HARDWARE)
0x78FC DESC ro — Module Description
  [31:16] DESC_MODULEID — Module identification contains a unique peripheral identification number. The assignments are maintained in a central database for all of the platform modules to ensure uniqueness.
  [15:12] DESC_FEATUREVER — Feature Set for the module *instance*
    0=DESC_FEATUREVER_VERSION_0 (VERSION_0); 1=DESC_FEATUREVER_VERSION_1 (VERSION_1)
  [7:4] DESC_MAJREV — Major rev of the IP
  [3:0] DESC_MINREV — Minor rev of the IP
0x7900 MCANSS_CLKEN — MCAN module clock enable
  [0] MCANSS_CLKEN_CLK_REQEN — MCAN functional and MCAN/MCANSS MMR clock request enable bit
    0=MCANSS_CLKEN_CLK_REQEN_CLR (CLR); 1=MCANSS_CLKEN_CLK_REQEN_SET (SET)
0x7904 MCANSS_CLKDIV — Clock divider
  [1:0] MCANSS_CLKDIV_RATIO — Clock divide ratio specification. Enables configuring clock divide settings for the MCAN functional clock input to the MCAN-SS.
    0=MCANSS_CLKDIV_RATIO_DIV_BY_1_ (DIV_BY_1_); 1=MCANSS_CLKDIV_RATIO_DIV_BY_2_ (DIV_BY_2_); 2=MCANSS_CLKDIV_RATIO_DIV_BY_4_ (DIV_BY_4_)
0x7908 MCANSS_CLKCTL — MCAN-SS clock stop control register
  [8] MCANSS_CLKCTL_WKUP_GLTFLT_EN — Setting this bit enables the glitch filter on MCAN RXD input, which wakes up the MCAN controller to exit clock gating.
    0=MCANSS_CLKCTL_WKUP_GLTFLT_EN_DISABLE (DISABLE); 1=MCANSS_CLKCTL_WKUP_GLTFLT_EN_ENABLE (ENABLE)
  [4] MCANSS_CLKCTL_WAKEUP_INT_EN — This bit contols enabling or disabling the MCAN IP clock stop wakeup interrupt (when MCANSS_CTRL.WAKEUPREQEN wakeup request is enabled to wakeup MCAN IP upon CAN RXD activity)
    0=MCANSS_CLKCTL_WAKEUP_INT_EN_DISABLE (DISABLE); 1=MCANSS_CLKCTL_WAKEUP_INT_EN_ENABLE (ENABLE)
  [0] MCANSS_CLKCTL_STOPREQ — This bit is used to enable/disable MCAN clock (both host clock and functional clock) gating request. Note: This bit can be reset by HW by Clock-Stop Wake-up via CAN RX Activity. See spec for more details.
    0=MCANSS_CLKCTL_STOPREQ_DISABLE (DISABLE); 1=MCANSS_CLKCTL_STOPREQ_ENABLE (ENABLE)
0x790C MCANSS_CLKSTS ro — MCANSS clock stop status register
  [8] MCANSS_CLKSTS_CCLKDONE — This bit indicates the status of MCAN contoller clock request from GPRCM.
    0=MCANSS_CLKSTS_CCLKDONE_RESET (RESET); 1=MCANSS_CLKSTS_CCLKDONE_SET (SET)
  [4] MCANSS_CLKSTS_STOPREQ_HW_OVR — MCANSS clock stop HW override status bit. This bit indicates when the MCANSS_CLKCTL.STOPREQ bit has been cleared by HW when a clock-stop wake-up event via CAN RX activity is trigged.
    0=MCANSS_CLKSTS_STOPREQ_HW_OVR_RESET (RESET); 1=MCANSS_CLKSTS_STOPREQ_HW_OVR_SET (SET)
  [0] MCANSS_CLKSTS_CLKSTOP_ACKSTS — Clock stop acknowledge status from MCAN IP
    0=MCANSS_CLKSTS_CLKSTOP_ACKSTS_RESET (RESET); 1=MCANSS_CLKSTS_CLKSTOP_ACKSTS_SET (SET)
